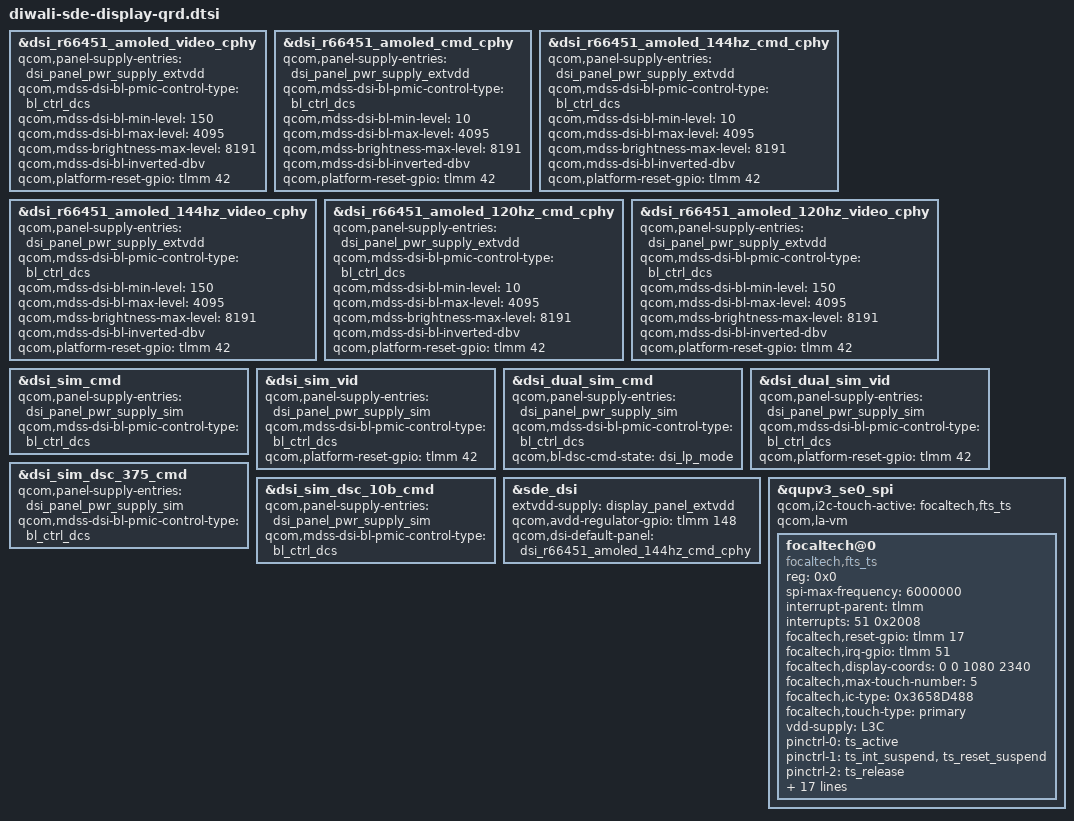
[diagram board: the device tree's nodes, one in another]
#include "diwali-sde-display.dtsi"

&dsi_r66451_amoled_video_cphy {
	qcom,panel-supply-entries = <&dsi_panel_pwr_supply_extvdd>;
	qcom,mdss-dsi-bl-pmic-control-type = "bl_ctrl_dcs";
	qcom,mdss-dsi-bl-min-level = <150>;
	qcom,mdss-dsi-bl-max-level = <4095>;
	qcom,mdss-brightness-max-level = <8191>;
	qcom,mdss-dsi-bl-inverted-dbv;
	qcom,platform-reset-gpio = <&tlmm 42 0>;
};

&dsi_r66451_amoled_cmd_cphy {
	qcom,panel-supply-entries = <&dsi_panel_pwr_supply_extvdd>;
	qcom,mdss-dsi-bl-pmic-control-type = "bl_ctrl_dcs";
	qcom,mdss-dsi-bl-min-level = <10>;
	qcom,mdss-dsi-bl-max-level = <4095>;
	qcom,mdss-brightness-max-level = <8191>;
	qcom,mdss-dsi-bl-inverted-dbv;
	qcom,platform-reset-gpio = <&tlmm 42 0>;
};

&dsi_r66451_amoled_144hz_cmd_cphy {
	qcom,panel-supply-entries = <&dsi_panel_pwr_supply_extvdd>;
	qcom,mdss-dsi-bl-pmic-control-type = "bl_ctrl_dcs";
	qcom,mdss-dsi-bl-min-level = <10>;
	qcom,mdss-dsi-bl-max-level = <4095>;
	qcom,mdss-brightness-max-level = <8191>;
	qcom,mdss-dsi-bl-inverted-dbv;
	qcom,platform-reset-gpio = <&tlmm 42 0>;
};

&dsi_r66451_amoled_144hz_video_cphy {
	qcom,panel-supply-entries = <&dsi_panel_pwr_supply_extvdd>;
	qcom,mdss-dsi-bl-pmic-control-type = "bl_ctrl_dcs";
	qcom,mdss-dsi-bl-min-level = <150>;
	qcom,mdss-dsi-bl-max-level = <4095>;
	qcom,mdss-brightness-max-level = <8191>;
	qcom,mdss-dsi-bl-inverted-dbv;
	qcom,platform-reset-gpio = <&tlmm 42 0>;
};

&dsi_r66451_amoled_120hz_cmd_cphy {
	qcom,panel-supply-entries = <&dsi_panel_pwr_supply_extvdd>;
	qcom,mdss-dsi-bl-pmic-control-type = "bl_ctrl_dcs";
	qcom,mdss-dsi-bl-min-level = <10>;
	qcom,mdss-dsi-bl-max-level = <4095>;
	qcom,mdss-brightness-max-level = <8191>;
	qcom,mdss-dsi-bl-inverted-dbv;
	qcom,platform-reset-gpio = <&tlmm 42 0>;
};

&dsi_r66451_amoled_120hz_video_cphy {
	qcom,panel-supply-entries = <&dsi_panel_pwr_supply_extvdd>;
	qcom,mdss-dsi-bl-pmic-control-type = "bl_ctrl_dcs";
	qcom,mdss-dsi-bl-min-level = <150>;
	qcom,mdss-dsi-bl-max-level = <4095>;
	qcom,mdss-brightness-max-level = <8191>;
	qcom,mdss-dsi-bl-inverted-dbv;
	qcom,platform-reset-gpio = <&tlmm 42 0>;
};

&dsi_sim_cmd {
	qcom,panel-supply-entries = <&dsi_panel_pwr_supply_sim>;
	qcom,mdss-dsi-bl-pmic-control-type = "bl_ctrl_dcs";
};

&dsi_sim_vid {
	qcom,panel-supply-entries = <&dsi_panel_pwr_supply_sim>;
	qcom,mdss-dsi-bl-pmic-control-type = "bl_ctrl_dcs";
	qcom,platform-reset-gpio = <&tlmm 42 0>;
};

&dsi_dual_sim_cmd {
	qcom,panel-supply-entries = <&dsi_panel_pwr_supply_sim>;
	qcom,mdss-dsi-bl-pmic-control-type = "bl_ctrl_dcs";
	qcom,bl-dsc-cmd-state = "dsi_lp_mode";
};

&dsi_dual_sim_vid {
	qcom,panel-supply-entries = <&dsi_panel_pwr_supply_sim>;
	qcom,mdss-dsi-bl-pmic-control-type = "bl_ctrl_dcs";
	qcom,platform-reset-gpio = <&tlmm 42 0>;
};

&dsi_sim_dsc_375_cmd {
	qcom,panel-supply-entries = <&dsi_panel_pwr_supply_sim>;
	qcom,mdss-dsi-bl-pmic-control-type = "bl_ctrl_dcs";
};

&dsi_sim_dsc_10b_cmd {
	qcom,panel-supply-entries = <&dsi_panel_pwr_supply_sim>;
	qcom,mdss-dsi-bl-pmic-control-type = "bl_ctrl_dcs";
};

&sde_dsi {
	extvdd-supply = <&display_panel_extvdd>;
	qcom,avdd-regulator-gpio = <&tlmm 148 0>;
	qcom,dsi-default-panel = <&dsi_r66451_amoled_144hz_cmd_cphy>;
};

&qupv3_se0_spi {
	#address-cells = <1>;
	#size-cells = <0>;

    status = "ok";
    qcom,i2c-touch-active = "focaltech,fts_ts";
    qcom,la-vm;

	focaltech@0 {
		        reg = <0x0>;
        compatible = "focaltech,fts_ts";
        spi-max-frequency = <6000000>;
        interrupt-parent = <&tlmm>;
        interrupts = <51 0x2008>;
        focaltech,reset-gpio = <&tlmm 17 0x00>;
        focaltech,irq-gpio = <&tlmm 51 0x2008>;
        focaltech,display-coords = <0 0 1080 2340>;
        focaltech,max-touch-number = <5>;
        focaltech,ic-type = <0x3658D488>;
        focaltech,touch-type = "primary";

        vdd-supply = <&L3C>;

        pinctrl-names = "pmx_ts_active", "pmx_ts_suspend", "pmx_ts_release";
        pinctrl-0 = <&ts_active>;
        pinctrl-1 = <&ts_int_suspend &ts_reset_suspend>;
        pinctrl-2 = <&ts_release>;

        focaltech,trusted-touch-mode = "vm_mode";
        focaltech,touch-environment = "pvm";
        focaltech,trusted-touch-type = "primary";
        focaltech,trusted-touch-spi-irq = <566>;
        focaltech,trusted-touch-io-bases = <0x980000 0x910000>;
        focaltech,trusted-touch-io-sizes = <0x1000 0x4000>;
        focaltech,trusted-touch-vm-gpio-list = <&tlmm 0 0 &tlmm 1 0 &tlmm 2 0
                        &tlmm 3 0 &tlmm 17 0 &tlmm 51 0x2008>;
		panel = <&dsi_r66451_amoled_144hz_cmd_cphy
			&dsi_r66451_amoled_144hz_video_cphy
			&dsi_r66451_amoled_video_cphy
			&dsi_r66451_amoled_cmd_cphy
			&dsi_r66451_amoled_120hz_cmd_cphy
			&dsi_r66451_amoled_120hz_video_cphy>;
	};
};
